AUTOSAR XML (schema 4-2-2)
package /Rte
  bsw module description Rte: module-id=255
    provided-entrys:
      bsw module entry RteInit: service-id=0x00, is-reentrant=false, is-synchronous=true, call-type=REGULAR
      bsw module entry RteStart: service-id=0x01, is-reentrant=false, is-synchronous=true, call-type=REGULAR
      bsw module entry RteStop: service-id=0x02, is-reentrant=false, is-synchronous=true, call-type=REGULAR
    bsw internal behavior RteBehavior
      bsw schedulable entity RteMainFunction: implemented-entry=RteMainFunction
  rte event InitEvent: start-on-event=InitRunnable
  rte event CyclicEvent_10ms: start-on-event=MainRunnable_10ms, period=0.01
  rte event CyclicEvent_100ms: start-on-event=MainRunnable_100ms, period=0.1
package /SwComponents
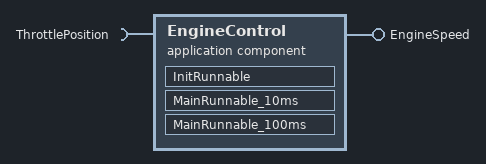
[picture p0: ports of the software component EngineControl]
  application sw component type EngineControl
    provide port EngineSpeed: nonqueued-sender-com-spec{data-element=Value, init-value=0}
    require port ThrottlePosition: nonqueued-receiver-com-spec{data-element=Value, filter=data-filter-type=ALWAYS, init-value=0}
    behavior EngineControlBehavior
      runnable InitRunnable: symbol=RE_EngineControl_Init
      runnable MainRunnable_10ms: minimum-start-interval=0.01, symbol=RE_EngineControl_Main_10ms
      runnable MainRunnable_100ms: minimum-start-interval=0.1, symbol=RE_EngineControl_Main_100ms
